# HK32L0xx register map
Vendor: HKMicroChip Ltd.; Series: HK32L0xx; File version: 1.3
CPU: CM0 r0p0, little endian, no MPU, no FPU, 3 interrupt priority bits
Registers are 32-bit, read-write, reset 0x0 unless marked. A register's access mark holds for its fields unless they carry their own. Offsets are from the block's base; [hi:lo] are bit positions; {n}, {i} and the like mark numbered series.

## TIM2
Base 0x40000000
Same registers: TIM3 0x40000400
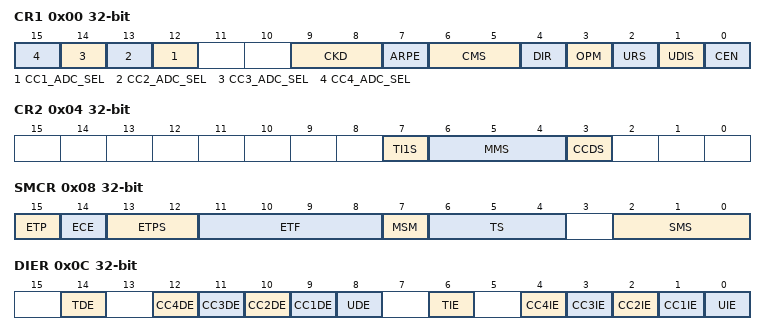
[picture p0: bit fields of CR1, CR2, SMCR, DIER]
0x00 CR1
  [n+11] CC{n}_ADC_SEL (n=1..4) — ADC trigger signal generation source
  [9:8] CKD — Clock division
  [7] ARPE — Auto-reload preload enable
  [6:5] CMS — Center-aligned mode selection
  [4] DIR — Direction
  [3] OPM — One pulse mode
  [2] URS — Update request source
  [1] UDIS — Update disable
  [0] CEN — Counter enable
0x04 CR2
  [7] TI1S — TI1 selection
  [6:4] MMS — Master mode selection
  [3] CCDS — Capture/Compare DMA selection
0x08 SMCR
  [15] ETP — External trigger polarity
  [14] ECE — External clock enable
  [13:12] ETPS — External trigger prescaler
  [11:8] ETF — External trigger filter
  [7] MSM — Master/Slave mode
  [6:4] TS — Tigger selection
  [2:0] SMS — Slave mode selection
0x0C DIER
  [14] TDE — Trigger DMA request enable
  [n+8] CC{n}DE (n=1..4) — Capture/Compare {n} DMA request enable
  [8] UDE — Update DMA request enable
  [6] TIE — Trigger interrupt enable
  [n] CC{n}IE (n=1..4) — Capture/Compare {n} interrupt enable
  [0] UIE — Update interrupt enable
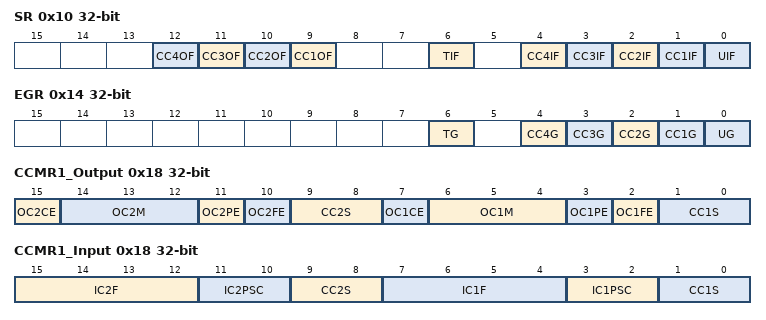
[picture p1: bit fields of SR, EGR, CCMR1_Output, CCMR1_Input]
0x10 SR
  [n+8] CC{n}OF (n=1..4) — Capture/Compare {n} overcapture flag
  [6] TIF — Trigger interrupt flag
  [n] CC{n}IF (n=1..4) — Capture/Compare {n} interrupt flag
  [0] UIF — Update interrupt flag
0x14 EGR wo
  [6] TG — Trigger generation
  [n] CC{n}G (n=1..4) — Capture/Compare {n} generation
  [0] UG — Update generation
0x18 CCMR1_Output
  [15] OC2CE — Output compare 2 clear enable
  [14:12] OC2M — Output compare 2 mode
  [11] OC2PE — Output compare 2 preload enable
  [10] OC2FE — Output compare 2 fast enable
  [9:8] CC2S — Capture/Compare 2 selection
  [7] OC1CE — Output compare 1 clear enable
  [6:4] OC1M — Output compare 1 mode
  [3] OC1PE — Output compare 1 preload enable
  [2] OC1FE — Output compare 1 fast enable
  [1:0] CC1S — Capture/Compare 1 selection
0x18 CCMR1_Input (alternate view of CCMR1_Output)
  [15:12] IC2F — Input capture 2 filter
  [11:10] IC2PSC — Input capture 2 prescaler
  [9:8] CC2S — Capture/Compare 2 selection
  [7:4] IC1F — Input capture 1 filter
  [3:2] IC1PSC — Input capture 1 prescaler
  [1:0] CC1S — Capture/Compare 1 selection
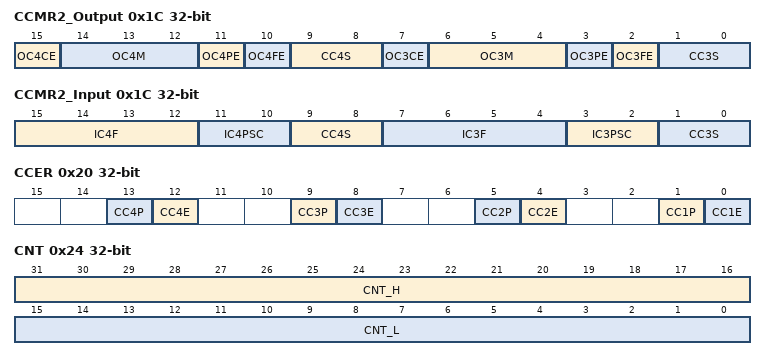
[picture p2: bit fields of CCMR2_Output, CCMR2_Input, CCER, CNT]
0x1C CCMR2_Output
  [15] OC4CE — Output compare 4 clear enable
  [14:12] OC4M — Output compare 4 mode
  [11] OC4PE — Output compare 4 preload enable
  [10] OC4FE — Output compare 4 fast enable
  [9:8] CC4S — Capture/Compare 4 selection
  [7] OC3CE — Output compare 3 clear enable
  [6:4] OC3M — Output compare 3 mode
  [3] OC3PE — Output compare 3 preload enable
  [2] OC3FE — Output compare 3 fast enable
  [1:0] CC3S — Capture/Compare 3 selection
0x1C CCMR2_Input (alternate view of CCMR2_Output)
  [15:12] IC4F — Input capture 4 filter
  [11:10] IC4PSC — Input capture 4 prescaler
  [9:8] CC4S — Capture/Compare 4 selection
  [7:4] IC3F — Input capture 3 filter
  [3:2] IC3PSC — Input capture 3 prescaler
  [1:0] CC3S — Capture/Compare 3 selection
0x20 CCER
  [4n-3] CC{n}P (n=1..4) — Capture/Compare {n} output Polarity
  [12] CC4E — Capture/Compare 4 output enable
  [8] CC3E — Capture/Compare 3 output enable
  [4] CC2E — Capture/Compare 2 output enable
  [0] CC1E — Capture/Compare 3 output enable
0x24 CNT
  [31:16] CNT_H — Counter value high bits of TIM2
  [15:0] CNT_L — Counter value
0x28 PSC
  [15:0] PSC — Prescaler value
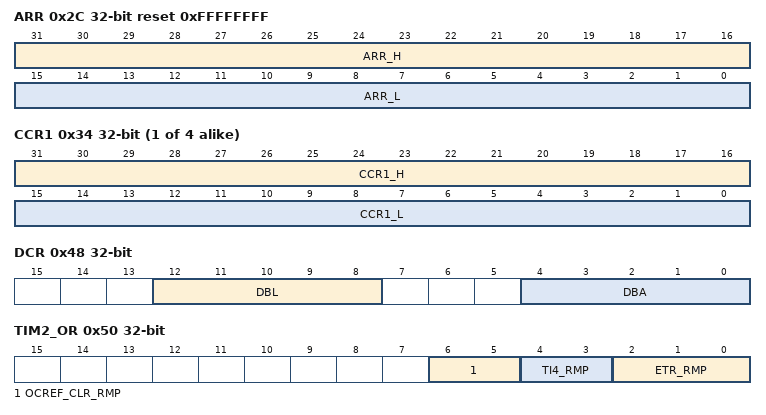
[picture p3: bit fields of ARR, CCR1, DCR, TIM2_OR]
0x2C ARR reset 0xFFFFFFFF
  [31:16] ARR_H — High auto-reload value high bits of TIM2
  [15:0] ARR_L — Low auto-reload value
{0x30+4i} CCR{i} (i=1..4)
  [31:16] CCR{i}_H — High Capture/Compare {i} value (Only TIM2)
  [15:0] CCR{i}_L — Low Capture/Compare {i} value
0x48 DCR
  [12:8] DBL — DMA burst length
  [4:0] DBA — DMA base address
0x4C DMAR
  [15:0] DMAB — DMA register for burst accesses
0x50 TIM2_OR
  [6:5] OCREF_CLR_RMP — Clear OCREF remap
  [4:3] TI4_RMP — Internal trigger remap
  [2:0] ETR_RMP — External trigger remap
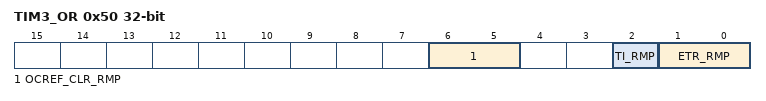
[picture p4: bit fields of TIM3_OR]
0x50 TIM3_OR (alternate view of TIM2_OR)
  [6:5] OCREF_CLR_RMP — Clear OCREF remap
  [2] TI_RMP — Internal trigger remap
  [1:0] ETR_RMP — External trigger remap
